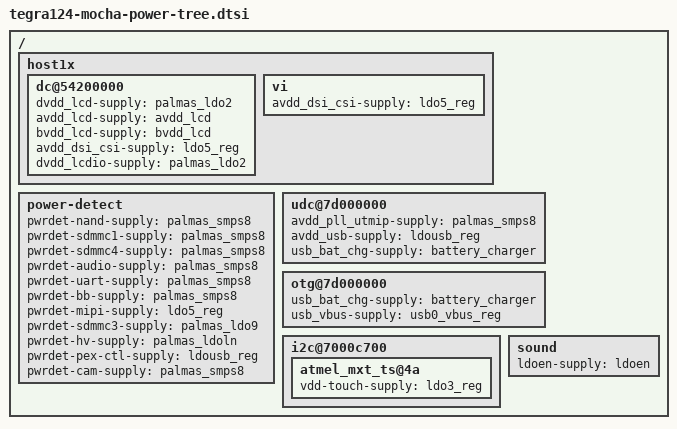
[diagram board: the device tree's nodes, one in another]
/*
 * arch/arm/boot/dts/tegra124-platforms/tegra124-mocha-power-tree.dtsi
 *
 * Copyright (c) 2017, SmokeTeam.  All rights reserved.
 *
 * This program is free software; you can redistribute it and/or modify
 * it under the terms of the GNU General Public License as published by
 * the Free Software Foundation; either version 2 of the License, or
 * (at your option) any later version.
 *
 * This program is distributed in the hope that it will be useful, but WITHOUT
 * ANY WARRANTY; without even the implied warranty of MERCHANTABILITY or
 * FITNESS FOR A PARTICULAR PURPOSE.  See the GNU General Public License for
 * more details.
 *
 * You should have received a copy of the GNU General Public License along
 * with this program; if not, write to the Free Software Foundation, Inc.,
 * 51 Franklin Street, Fifth Floor, Boston, MA  02110-1301, USA.
 */

#include "tegra124-mocha-pmic-e1736.dtsi"
#include "tegra124-mocha-fixed-e1736.dtsi"

/ {

	host1x {
		/* tegradc.0 */
		dc@54200000 {
			dvdd_lcd-supply = <&palmas_ldo2>;
			avdd_lcd-supply = <&avdd_lcd>;
			bvdd_lcd-supply = <&bvdd_lcd>;
			avdd_dsi_csi-supply = <&ldo5_reg>;
			dvdd_lcdio-supply = <&palmas_ldo2>;
		};
		vi {
			avdd_dsi_csi-supply = <&ldo5_reg>;
		};
	};

	power-detect {
		pwrdet-nand-supply = <&palmas_smps8>;
		pwrdet-sdmmc1-supply = <&palmas_smps8>;
		pwrdet-sdmmc4-supply = <&palmas_smps8>;
		pwrdet-audio-supply = <&palmas_smps8>;
		pwrdet-uart-supply = <&palmas_smps8>;
		pwrdet-bb-supply = <&palmas_smps8>;
		pwrdet-mipi-supply = <&ldo5_reg>;
		pwrdet-sdmmc3-supply = <&palmas_ldo9>;
		pwrdet-hv-supply = <&palmas_ldoln>;
		pwrdet-pex-ctl-supply = <&ldousb_reg>;
		pwrdet-cam-supply = <&palmas_smps8>;
	};

	udc@7d000000 {
		avdd_pll_utmip-supply = <&palmas_smps8>;
		avdd_usb-supply = <&ldousb_reg>;
		usb_bat_chg-supply = <&battery_charger>;
	};

	otg@7d000000 {
		usb_bat_chg-supply = <&battery_charger>;
		usb_vbus-supply = <&usb0_vbus_reg>;
	};
	
	i2c@7000c700 {
		atmel_mxt_ts@4a {
			vdd-touch-supply = <&ldo3_reg>;
		};
	};
	sound {
		ldoen-supply = <&ldoen>;
	};
};
